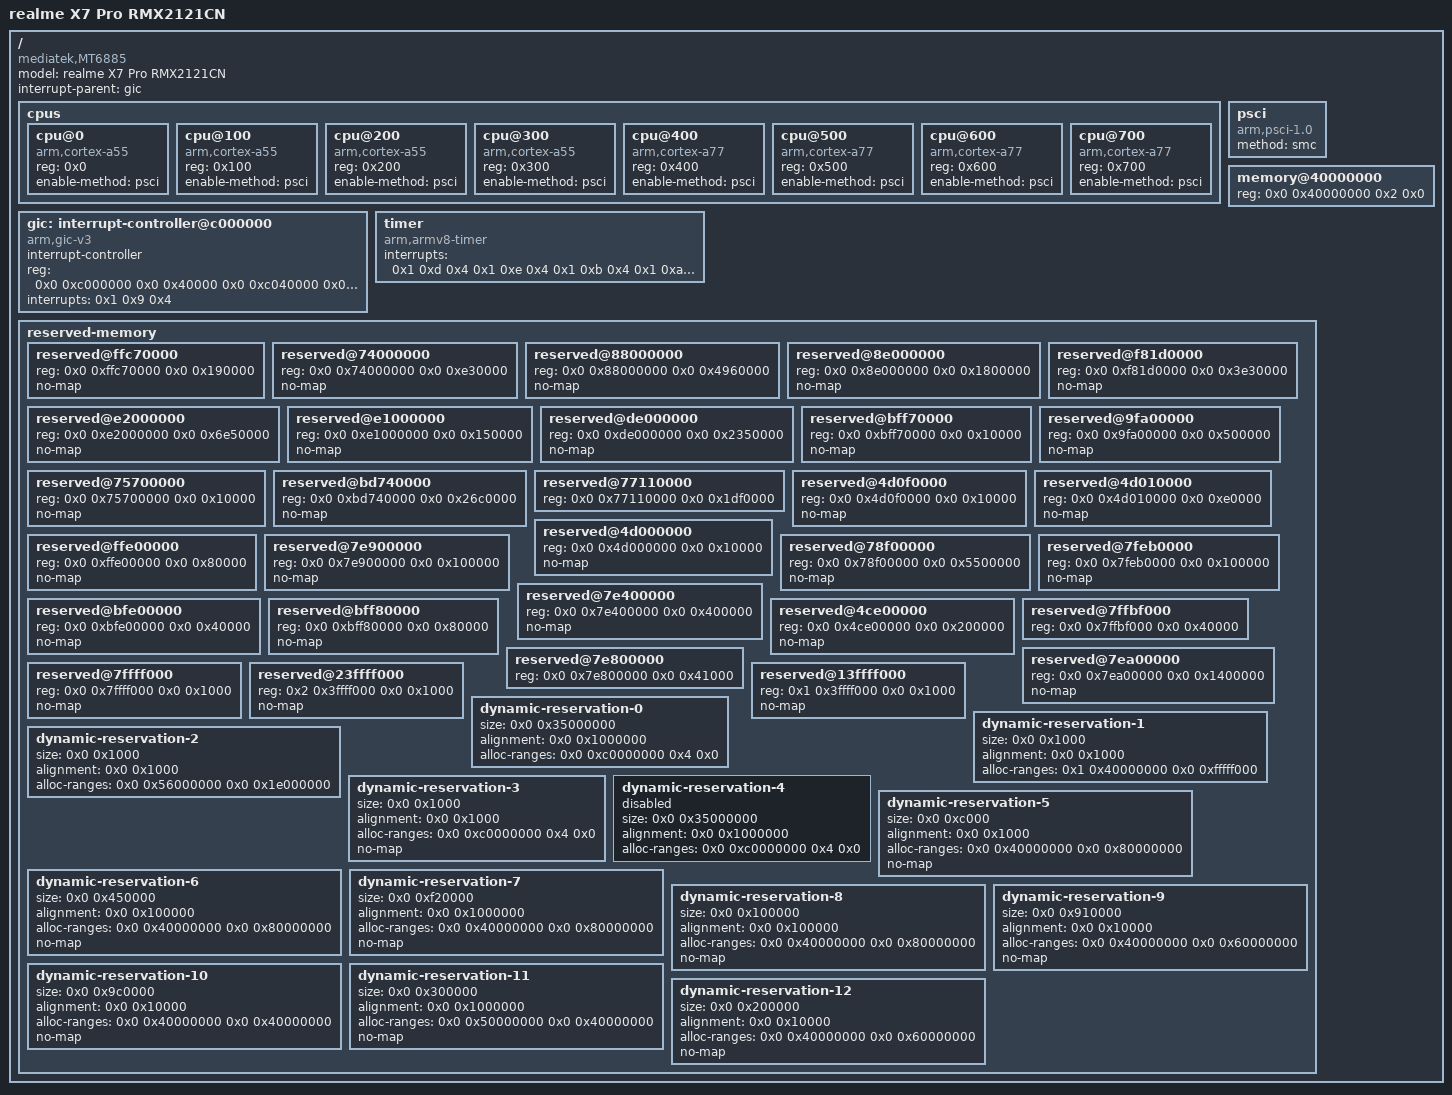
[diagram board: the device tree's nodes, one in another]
// SPDX-License-Identifier: GPL-2.0-only
/dts-v1/;

/*
 * OFFLINE DRAFT ONLY: not a board-support implementation or flashable firmware.
 * Binding reference: Android common 846dd6f9b6c61b6aa95e141455ce8f0ea44b29ef.
 * Addresses are snapshots from the normal diagnostic boot, not recovery.
 * Bootloader injection, dynamic allocations and a usable log channel remain unresolved.
 * Vendor reservation compatibles are intentionally omitted: reservation only,
 * without claiming that CMA/DMA/secure-world consumers have been ported.
 */
/ {
	compatible = "mediatek,MT6885";
	/* Authored board description; not copied from a live FDT property. */
	model = "realme X7 Pro RMX2121CN";
	#address-cells = <2>;
	#size-cells = <2>;
	interrupt-parent = <&gic>;

	cpus {
		#address-cells = <1>;
		#size-cells = <0>;

		/* MPIDR copied from /cpus/cpu@000; core type from runtime CPU ID. */
		cpu@0 {
			device_type = "cpu";
			compatible = "arm,cortex-a55";
			reg = <0x0>;
			enable-method = "psci";
		};

		/* MPIDR copied from /cpus/cpu@001; core type from runtime CPU ID. */
		cpu@100 {
			device_type = "cpu";
			compatible = "arm,cortex-a55";
			reg = <0x100>;
			enable-method = "psci";
		};

		/* MPIDR copied from /cpus/cpu@002; core type from runtime CPU ID. */
		cpu@200 {
			device_type = "cpu";
			compatible = "arm,cortex-a55";
			reg = <0x200>;
			enable-method = "psci";
		};

		/* MPIDR copied from /cpus/cpu@003; core type from runtime CPU ID. */
		cpu@300 {
			device_type = "cpu";
			compatible = "arm,cortex-a55";
			reg = <0x300>;
			enable-method = "psci";
		};

		/* MPIDR copied from /cpus/cpu@100; core type from runtime CPU ID. */
		cpu@400 {
			device_type = "cpu";
			compatible = "arm,cortex-a77";
			reg = <0x400>;
			enable-method = "psci";
		};

		/* MPIDR copied from /cpus/cpu@101; core type from runtime CPU ID. */
		cpu@500 {
			device_type = "cpu";
			compatible = "arm,cortex-a77";
			reg = <0x500>;
			enable-method = "psci";
		};

		/* MPIDR copied from /cpus/cpu@102; core type from runtime CPU ID. */
		cpu@600 {
			device_type = "cpu";
			compatible = "arm,cortex-a77";
			reg = <0x600>;
			enable-method = "psci";
		};

		/* MPIDR copied from /cpus/cpu@103; core type from runtime CPU ID. */
		cpu@700 {
			device_type = "cpu";
			compatible = "arm,cortex-a77";
			reg = <0x700>;
			enable-method = "psci";
		};
	};

	psci {
		compatible = "arm,psci-1.0";
		method = "smc";
	};

	gic: interrupt-controller@c000000 {
		compatible = "arm,gic-v3";
		#interrupt-cells = <3>;
		#address-cells = <0>;
		interrupt-controller;
		reg = <0x0 0xc000000 0x0 0x40000 0x0 0xc040000 0x0 0x200000>;
		interrupts = <0x1 0x9 0x4>;
	};

	timer {
		compatible = "arm,armv8-timer";
		interrupts = <0x1 0xd 0x4 0x1 0xe 0x4 0x1 0xb 0x4 0x1 0xa 0x4>;
		/* No CNTFRQ override: the old DT/log report 13 MHz, but no firmware error is proven. */
	};

	memory@40000000 {
		device_type = "memory";
		reg = <0x0 0x40000000 0x2 0x0>;
	};

	reserved-memory {
		#address-cells = <2>;
		#size-cells = <2>;
		ranges;

		/* Source: /reserved-memory/mblock-30-DPM-reserved */
		reserved@ffc70000 {
			reg = <0x0 0xffc70000 0x0 0x190000>;
			no-map;
		};

		/* Source: /reserved-memory/mblock-29-mediatek,reserve-memory-adsp */
		reserved@74000000 {
			reg = <0x0 0x74000000 0x0 0xe30000>;
			no-map;
		};

		/* Source: /reserved-memory/mblock-28-ap_md_c_smem */
		reserved@88000000 {
			reg = <0x0 0x88000000 0x0 0x4960000>;
			no-map;
		};

		/* Source: /reserved-memory/mblock-27-ap_md_nc_smem */
		reserved@8e000000 {
			reg = <0x0 0x8e000000 0x0 0x1800000>;
			no-map;
		};

		/* Source: /reserved-memory/mblock-26-md_mem_usage */
		reserved@f81d0000 {
			reg = <0x0 0xf81d0000 0x0 0x3e30000>;
			no-map;
		};

		/* Source: /reserved-memory/mblock-25-md_mem_usage */
		reserved@e2000000 {
			reg = <0x0 0xe2000000 0x0 0x6e50000>;
			no-map;
		};

		/* Source: /reserved-memory/mblock-24-md_mem_usage */
		reserved@e1000000 {
			reg = <0x0 0xe1000000 0x0 0x150000>;
			no-map;
		};

		/* Source: /reserved-memory/mblock-23-md_mem_usage */
		reserved@de000000 {
			reg = <0x0 0xde000000 0x0 0x2350000>;
			no-map;
		};

		/* Source: /reserved-memory/mblock-22-ccci_tag_mem */
		reserved@bff70000 {
			reg = <0x0 0xbff70000 0x0 0x10000>;
			no-map;
		};

		/* Source: /reserved-memory/mblock-21-SCP-reserved */
		reserved@9fa00000 {
			reg = <0x0 0x9fa00000 0x0 0x500000>;
			no-map;
		};

		/* Source: /reserved-memory/mblock-20-SPM-reserved */
		reserved@75700000 {
			reg = <0x0 0x75700000 0x0 0x10000>;
			no-map;
		};

		/* Source: /reserved-memory/mblock-19-vpu_binary */
		reserved@bd740000 {
			reg = <0x0 0xbd740000 0x0 0x26c0000>;
			no-map;
		};

		/* Source: /reserved-memory/mblock-18-framebuffer */
		reserved@77110000 {
			reg = <0x0 0x77110000 0x0 0x1df0000>;
		};

		/* Source: /reserved-memory/mblock-17-minirdump */
		reserved@4d0f0000 {
			reg = <0x0 0x4d0f0000 0x0 0x10000>;
			no-map;
		};

		/* Source: /reserved-memory/mblock-16-pstore */
		reserved@4d010000 {
			reg = <0x0 0x4d010000 0x0 0xe0000>;
			no-map;
		};

		/* Source: /reserved-memory/mblock-15-aee_debug_kinfo */
		reserved@4d000000 {
			reg = <0x0 0x4d000000 0x0 0x10000>;
			no-map;
		};

		/* Source: /reserved-memory/mblock-14-PICACHU */
		reserved@ffe00000 {
			reg = <0x0 0xffe00000 0x0 0x80000>;
			no-map;
		};

		/* Source: /reserved-memory/mblock-13-MCUPM-reserved */
		reserved@7e900000 {
			reg = <0x0 0x7e900000 0x0 0x100000>;
			no-map;
		};

		/* Source: /reserved-memory/mblock-12-tee-reserved */
		reserved@78f00000 {
			reg = <0x0 0x78f00000 0x0 0x5500000>;
			no-map;
		};

		/* Source: /reserved-memory/mblock-11-SSPM-reserved */
		reserved@7feb0000 {
			reg = <0x0 0x7feb0000 0x0 0x100000>;
			no-map;
		};

		/* Source: /reserved-memory/mblock-10-tee-secmem */
		reserved@7e400000 {
			reg = <0x0 0x7e400000 0x0 0x400000>;
			no-map;
		};

		/* Source: /reserved-memory/mblock-9-atf-log-reserved */
		reserved@bfe00000 {
			reg = <0x0 0xbfe00000 0x0 0x40000>;
			no-map;
		};

		/* Source: /reserved-memory/mblock-8-atf-ramdump-reserved */
		reserved@bff80000 {
			reg = <0x0 0xbff80000 0x0 0x80000>;
			no-map;
		};

		/* Source: /reserved-memory/mblock-7-atf-reserved */
		reserved@4ce00000 {
			reg = <0x0 0x4ce00000 0x0 0x200000>;
			no-map;
		};

		/* Source: /reserved-memory/mblock-6-log_store */
		reserved@7ffbf000 {
			reg = <0x0 0x7ffbf000 0x0 0x40000>;
		};

		/* Source: /reserved-memory/mblock-5-gz-log */
		reserved@7e800000 {
			reg = <0x0 0x7e800000 0x0 0x41000>;
		};

		/* Source: /reserved-memory/mblock-4-gz */
		reserved@7ea00000 {
			reg = <0x0 0x7ea00000 0x0 0x1400000>;
			no-map;
		};

		/* Source: /reserved-memory/mblock-3-emi_mbist_buf */
		reserved@7ffff000 {
			reg = <0x0 0x7ffff000 0x0 0x1000>;
			no-map;
		};

		/* Source: /reserved-memory/mblock-2-dramc-rk1 */
		reserved@23ffff000 {
			reg = <0x2 0x3ffff000 0x0 0x1000>;
			no-map;
		};

		/* Source: /reserved-memory/mblock-1-dramc-rk0 */
		reserved@13ffff000 {
			reg = <0x1 0x3ffff000 0x0 0x1000>;
			no-map;
		};

		/* Source: /reserved-memory/zone-movable-cma-memory */
		dynamic-reservation-0 {
			size = <0x0 0x35000000>;
			alignment = <0x0 0x1000000>;
			alloc-ranges = <0x0 0xc0000000 0x4 0x0>;
		};

		/* Source: /reserved-memory/reserve-memory-dram_r1_dummy_read */
		dynamic-reservation-1 {
			size = <0x0 0x1000>;
			alignment = <0x0 0x1000>;
			alloc-ranges = <0x1 0x40000000 0x0 0xfffff000>;
		};

		/* Source: /reserved-memory/reserve-memory-dram_r0_dummy_read */
		dynamic-reservation-2 {
			size = <0x0 0x1000>;
			alignment = <0x0 0x1000>;
			alloc-ranges = <0x0 0x56000000 0x0 0x1e000000>;
		};

		/* Source: /reserved-memory/reserve-memory-ssmr */
		dynamic-reservation-3 {
			size = <0x0 0x1000>;
			alignment = <0x0 0x1000>;
			alloc-ranges = <0x0 0xc0000000 0x4 0x0>;
			no-map;
		};

		/* Source: /reserved-memory/zmc-default */
		dynamic-reservation-4 {
			size = <0x0 0x35000000>;
			alignment = <0x0 0x1000000>;
			alloc-ranges = <0x0 0xc0000000 0x4 0x0>;
			status = "disabled";
		};

		/* Source: /reserved-memory/ion-carveout-heap */
		dynamic-reservation-5 {
			size = <0x0 0xc000>;
			alignment = <0x0 0x1000>;
			alloc-ranges = <0x0 0x40000000 0x0 0x80000000>;
			no-map;
		};

		/* Source: /reserved-memory/consys-reserve-memory */
		dynamic-reservation-6 {
			size = <0x0 0x450000>;
			alignment = <0x0 0x100000>;
			alloc-ranges = <0x0 0x40000000 0x0 0x80000000>;
			no-map;
		};

		/* Source: /reserved-memory/wifi-reserve-memory */
		dynamic-reservation-7 {
			size = <0x0 0xf20000>;
			alignment = <0x0 0x1000000>;
			alloc-ranges = <0x0 0x40000000 0x0 0x80000000>;
			no-map;
		};

		/* Source: /reserved-memory/gps-reserve-memory */
		dynamic-reservation-8 {
			size = <0x0 0x100000>;
			alignment = <0x0 0x100000>;
			alloc-ranges = <0x0 0x40000000 0x0 0x80000000>;
			no-map;
		};

		/* Source: /reserved-memory/reserve-memory-sspm_share */
		dynamic-reservation-9 {
			size = <0x0 0x910000>;
			alignment = <0x0 0x10000>;
			alloc-ranges = <0x0 0x40000000 0x0 0x60000000>;
			no-map;
			status = "okay";
		};

		/* Source: /reserved-memory/reserve-memory-adsp_share */
		dynamic-reservation-10 {
			size = <0x0 0x9c0000>;
			alignment = <0x0 0x10000>;
			alloc-ranges = <0x0 0x40000000 0x0 0x40000000>;
			no-map;
		};

		/* Source: /reserved-memory/reserve-memory-scp_share */
		dynamic-reservation-11 {
			size = <0x0 0x300000>;
			alignment = <0x0 0x1000000>;
			alloc-ranges = <0x0 0x50000000 0x0 0x40000000>;
			no-map;
		};

		/* Source: /reserved-memory/reserve-memory-mcupm_share */
		dynamic-reservation-12 {
			size = <0x0 0x200000>;
			alignment = <0x0 0x10000>;
			alloc-ranges = <0x0 0x40000000 0x0 0x60000000>;
			no-map;
			status = "okay";
		};
	};
};
